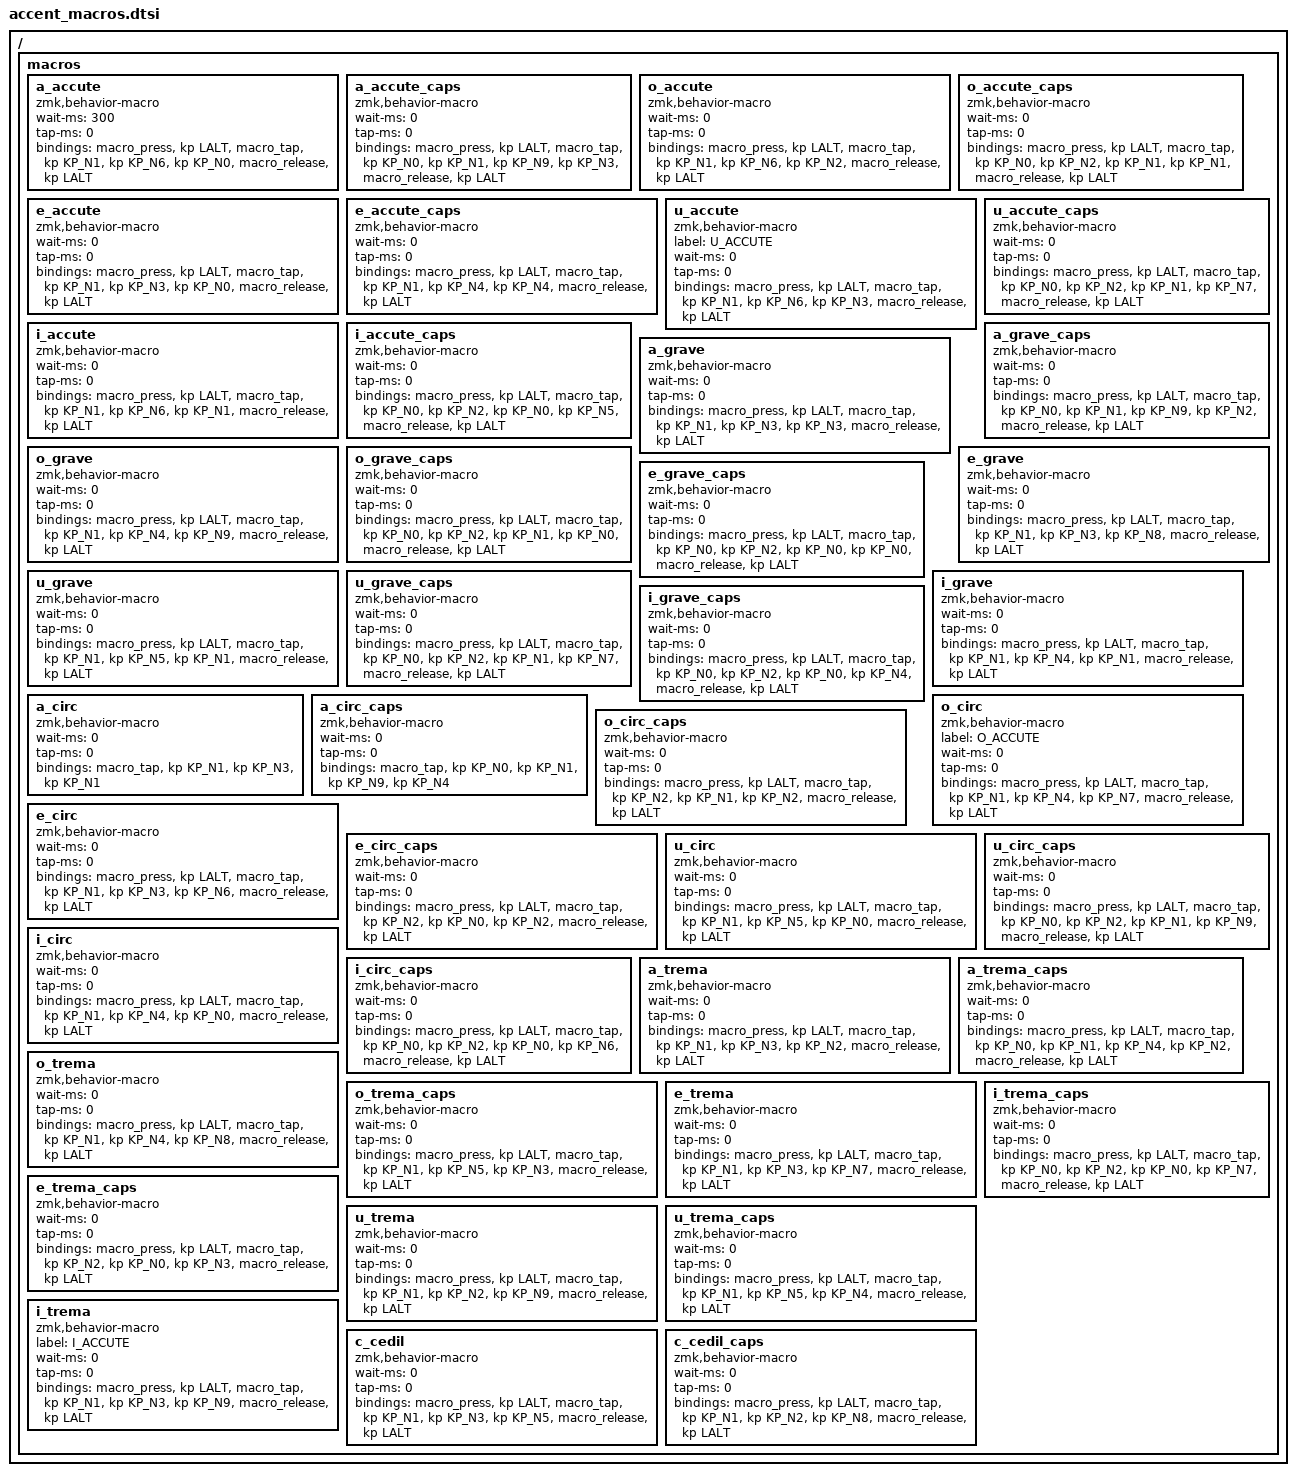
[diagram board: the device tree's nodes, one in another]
/ {
    macros {
        a_accute: a_accute {
            compatible = "zmk,behavior-macro";
            #binding-cells = <0>;
            wait-ms = <300>;
            tap-ms = <0>;
            bindings
            = <&macro_press   &kp LALT>
            , <&macro_tap     &kp KP_N1 &kp KP_N6 &kp KP_N0>
            , <&macro_release &kp LALT>;
        };

        a_accute_caps: a_accute_caps {
            compatible = "zmk,behavior-macro";
            #binding-cells = <0>;
            wait-ms = <0>;
            tap-ms = <0>;
            bindings
            = <&macro_press   &kp LALT>
            , <&macro_tap     &kp KP_N0 &kp KP_N1 &kp KP_N9 &kp KP_N3>
            , <&macro_release &kp LALT>;
        };

        o_accute: o_accute {
            compatible = "zmk,behavior-macro";
            #binding-cells = <0>;
            wait-ms = <0>;
            tap-ms = <0>;
            bindings
            = <&macro_press   &kp LALT>
            , <&macro_tap     &kp KP_N1 &kp KP_N6 &kp KP_N2>
            , <&macro_release &kp LALT>;
        };

        o_accute_caps: o_accute_caps {
            compatible = "zmk,behavior-macro";
            #binding-cells = <0>;
            wait-ms = <0>;
            tap-ms = <0>;
            bindings
            = <&macro_press   &kp LALT>
            , <&macro_tap     &kp KP_N0 &kp KP_N2 &kp KP_N1 &kp KP_N1>
            , <&macro_release &kp LALT>;
        };

        e_accute: e_accute {
            compatible = "zmk,behavior-macro";
            #binding-cells = <0>;
            wait-ms = <0>;
            tap-ms = <0>;
            bindings
            = <&macro_press   &kp LALT>
            , <&macro_tap     &kp KP_N1 &kp KP_N3 &kp KP_N0>
            , <&macro_release &kp LALT>;
        };

        e_accute_caps: e_accute_caps {
            compatible = "zmk,behavior-macro";
            #binding-cells = <0>;
            wait-ms = <0>;
            tap-ms = <0>;
            bindings
            = <&macro_press   &kp LALT>
            , <&macro_tap     &kp KP_N1 &kp KP_N4 &kp KP_N4>
            , <&macro_release &kp LALT>;
        };

        u_accute: u_accute {
            label = "U_ACCUTE";
            compatible = "zmk,behavior-macro";
            #binding-cells = <0>;
            wait-ms = <0>;
            tap-ms = <0>;
            bindings
            = <&macro_press   &kp LALT>
            , <&macro_tap     &kp KP_N1 &kp KP_N6 &kp KP_N3>
            , <&macro_release &kp LALT>;
        };

        u_accute_caps: u_accute_caps {
            compatible = "zmk,behavior-macro";
            #binding-cells = <0>;
            wait-ms = <0>;
            tap-ms = <0>;
            bindings
            = <&macro_press   &kp LALT>
            , <&macro_tap     &kp KP_N0 &kp KP_N2 &kp KP_N1 &kp KP_N7>
            , <&macro_release &kp LALT>;
        };

        i_accute: i_accute {
            compatible = "zmk,behavior-macro";
            #binding-cells = <0>;
            wait-ms = <0>;
            tap-ms = <0>;
            bindings
            = <&macro_press   &kp LALT>
            , <&macro_tap     &kp KP_N1 &kp KP_N6 &kp KP_N1>
            , <&macro_release &kp LALT>;
        };

        i_accute_caps: i_accute_caps {
            compatible = "zmk,behavior-macro";
            #binding-cells = <0>;
            wait-ms = <0>;
            tap-ms = <0>;
            bindings
            = <&macro_press   &kp LALT>
            , <&macro_tap     &kp KP_N0 &kp KP_N2 &kp KP_N0 &kp KP_N5>
            , <&macro_release &kp LALT>;
        };


        a_grave: a_grave {
            compatible = "zmk,behavior-macro";
            #binding-cells = <0>;
            wait-ms = <0>;
            tap-ms = <0>;
            bindings
            = <&macro_press   &kp LALT>
            , <&macro_tap     &kp KP_N1 &kp KP_N3 &kp KP_N3>
            , <&macro_release &kp LALT>;
        };

        a_grave_caps: a_grave_caps {
            compatible = "zmk,behavior-macro";
            #binding-cells = <0>;
            wait-ms = <0>;
            tap-ms = <0>;
            bindings
            = <&macro_press   &kp LALT>
            , <&macro_tap     &kp KP_N0 &kp KP_N1 &kp KP_N9 &kp KP_N2>
            , <&macro_release &kp LALT>;
        };

        o_grave: o_grave {
            compatible = "zmk,behavior-macro";
            #binding-cells = <0>;
            wait-ms = <0>;
            tap-ms = <0>;
            bindings
            = <&macro_press   &kp LALT>
            , <&macro_tap     &kp KP_N1 &kp KP_N4 &kp KP_N9>
            , <&macro_release &kp LALT>;
        };

        o_grave_caps: o_grave_caps {
            compatible = "zmk,behavior-macro";
            #binding-cells = <0>;
            wait-ms = <0>;
            tap-ms = <0>;
            bindings
            = <&macro_press   &kp LALT>
            , <&macro_tap     &kp KP_N0 &kp KP_N2 &kp KP_N1 &kp KP_N0>
            , <&macro_release &kp LALT>;
        };

        e_grave: e_grave {
            compatible = "zmk,behavior-macro";
            #binding-cells = <0>;
            wait-ms = <0>;
            tap-ms = <0>;
            bindings
            = <&macro_press   &kp LALT>
            , <&macro_tap     &kp KP_N1 &kp KP_N3 &kp KP_N8>
            , <&macro_release &kp LALT>;
        };

        e_grave_caps: e_grave_caps {
            compatible = "zmk,behavior-macro";
            #binding-cells = <0>;
            wait-ms = <0>;
            tap-ms = <0>;
            bindings
            = <&macro_press   &kp LALT>
            , <&macro_tap     &kp KP_N0 &kp KP_N2 &kp KP_N0 &kp KP_N0>
            , <&macro_release &kp LALT>;
        };

        u_grave: u_grave {
            compatible = "zmk,behavior-macro";
            #binding-cells = <0>;
            wait-ms = <0>;
            tap-ms = <0>;
            bindings
            = <&macro_press   &kp LALT>
            , <&macro_tap     &kp KP_N1 &kp KP_N5 &kp KP_N1>
            , <&macro_release &kp LALT>;
        };

        u_grave_caps: u_grave_caps {
            compatible = "zmk,behavior-macro";
            #binding-cells = <0>;
            wait-ms = <0>;
            tap-ms = <0>;
            bindings
            = <&macro_press   &kp LALT>
            , <&macro_tap     &kp KP_N0 &kp KP_N2 &kp KP_N1 &kp KP_N7>
            , <&macro_release &kp LALT>;
        };

        i_grave: i_grave {
            compatible = "zmk,behavior-macro";
            #binding-cells = <0>;
            wait-ms = <0>;
            tap-ms = <0>;
            bindings
            = <&macro_press   &kp LALT>
            , <&macro_tap     &kp KP_N1 &kp KP_N4 &kp KP_N1>
            , <&macro_release &kp LALT>;
        };

        i_grave_caps: i_grave_caps {
            compatible = "zmk,behavior-macro";
            #binding-cells = <0>;
            wait-ms = <0>;
            tap-ms = <0>;
            bindings
            = <&macro_press   &kp LALT>
            , <&macro_tap     &kp KP_N0 &kp KP_N2 &kp KP_N0 &kp KP_N4>
            , <&macro_release &kp LALT>;
        };


        a_circ: a_circ {
            compatible = "zmk,behavior-macro";
            #binding-cells = <0>;
            wait-ms = <0>;
            tap-ms = <0>;
            bindings = <&macro_tap &kp KP_N1 &kp KP_N3 &kp KP_N1>;
        };

        a_circ_caps: a_circ_caps {
            compatible = "zmk,behavior-macro";
            #binding-cells = <0>;
            wait-ms = <0>;
            tap-ms = <0>;
            bindings = <&macro_tap &kp KP_N0 &kp KP_N1 &kp KP_N9 &kp KP_N4>;
        };

        o_circ: o_circ {
            label = "O_ACCUTE";
            compatible = "zmk,behavior-macro";
            #binding-cells = <0>;
            wait-ms = <0>;
            tap-ms = <0>;
            bindings
            = <&macro_press   &kp LALT>
            , <&macro_tap     &kp KP_N1 &kp KP_N4 &kp KP_N7>
            , <&macro_release &kp LALT>;
        };

        o_circ_caps: o_circ_caps {
            compatible = "zmk,behavior-macro";
            #binding-cells = <0>;
            wait-ms = <0>;
            tap-ms = <0>;
            bindings
            = <&macro_press   &kp LALT>
            , <&macro_tap     &kp KP_N2 &kp KP_N1 &kp KP_N2>
            , <&macro_release &kp LALT>;
        };

        e_circ: e_circ {
            compatible = "zmk,behavior-macro";
            #binding-cells = <0>;
            wait-ms = <0>;
            tap-ms = <0>;
            bindings
            = <&macro_press   &kp LALT>
            , <&macro_tap     &kp KP_N1 &kp KP_N3 &kp KP_N6>
            , <&macro_release &kp LALT>;
        };

        e_circ_caps: e_circ_caps {
            compatible = "zmk,behavior-macro";
            #binding-cells = <0>;
            wait-ms = <0>;
            tap-ms = <0>;
            bindings
            = <&macro_press   &kp LALT>
            , <&macro_tap     &kp KP_N2 &kp KP_N0 &kp KP_N2>
            , <&macro_release &kp LALT>;
        };

        u_circ: u_circ {
            compatible = "zmk,behavior-macro";
            #binding-cells = <0>;
            wait-ms = <0>;
            tap-ms = <0>;
            bindings
            = <&macro_press   &kp LALT>
            , <&macro_tap     &kp KP_N1 &kp KP_N5 &kp KP_N0>
            , <&macro_release &kp LALT>;
        };

        u_circ_caps: u_circ_caps {
            compatible = "zmk,behavior-macro";
            #binding-cells = <0>;
            wait-ms = <0>;
            tap-ms = <0>;
            bindings
            = <&macro_press   &kp LALT>
            , <&macro_tap     &kp KP_N0 &kp KP_N2 &kp KP_N1 &kp KP_N9>
            , <&macro_release &kp LALT>;
        };

        i_circ: i_circ {
            compatible = "zmk,behavior-macro";
            #binding-cells = <0>;
            wait-ms = <0>;
            tap-ms = <0>;
            bindings
            = <&macro_press   &kp LALT>
            , <&macro_tap     &kp KP_N1 &kp KP_N4 &kp KP_N0>
            , <&macro_release &kp LALT>;
        };

        i_circ_caps: i_circ_caps {
            compatible = "zmk,behavior-macro";
            #binding-cells = <0>;
            wait-ms = <0>;
            tap-ms = <0>;
            bindings
            = <&macro_press   &kp LALT>
            , <&macro_tap     &kp KP_N0 &kp KP_N2 &kp KP_N0 &kp KP_N6>
            , <&macro_release &kp LALT>;
        };

        a_trema: a_trema {
            compatible = "zmk,behavior-macro";
            #binding-cells = <0>;
            wait-ms = <0>;
            tap-ms = <0>;
            bindings
            = <&macro_press   &kp LALT>
            , <&macro_tap     &kp KP_N1 &kp KP_N3 &kp KP_N2>
            , <&macro_release &kp LALT>;
        };

        a_trema_caps: a_trema_caps {
            compatible = "zmk,behavior-macro";
            #binding-cells = <0>;
            wait-ms = <0>;
            tap-ms = <0>;
            bindings
            = <&macro_press   &kp LALT>
            , <&macro_tap     &kp KP_N0 &kp KP_N1 &kp KP_N4 &kp KP_N2>
            , <&macro_release &kp LALT>;
        };

        o_trema: o_trema {
            compatible = "zmk,behavior-macro";
            #binding-cells = <0>;
            wait-ms = <0>;
            tap-ms = <0>;
            bindings
            = <&macro_press   &kp LALT>
            , <&macro_tap     &kp KP_N1 &kp KP_N4 &kp KP_N8>
            , <&macro_release &kp LALT>;
        };

        o_trema_caps: o_trema_caps {
            compatible = "zmk,behavior-macro";
            #binding-cells = <0>;
            wait-ms = <0>;
            tap-ms = <0>;
            bindings
            = <&macro_press   &kp LALT>
            , <&macro_tap     &kp KP_N1 &kp KP_N5 &kp KP_N3>
            , <&macro_release &kp LALT>;
        };

        e_trema: e_trema {
            compatible = "zmk,behavior-macro";
            #binding-cells = <0>;
            wait-ms = <0>;
            tap-ms = <0>;
            bindings
            = <&macro_press   &kp LALT>
            , <&macro_tap     &kp KP_N1 &kp KP_N3 &kp KP_N7>
            , <&macro_release &kp LALT>;
        };

        e_trema_caps: e_trema_caps {
            compatible = "zmk,behavior-macro";
            #binding-cells = <0>;
            wait-ms = <0>;
            tap-ms = <0>;
            bindings
            = <&macro_press   &kp LALT>
            , <&macro_tap     &kp KP_N2 &kp KP_N0 &kp KP_N3>
            , <&macro_release &kp LALT>;
        };

        u_trema: u_trema {
            compatible = "zmk,behavior-macro";
            #binding-cells = <0>;
            wait-ms = <0>;
            tap-ms = <0>;
            bindings
            = <&macro_press   &kp LALT>
            , <&macro_tap     &kp KP_N1 &kp KP_N2 &kp KP_N9>
            , <&macro_release &kp LALT>;
        };

        u_trema_caps: u_trema_caps {
            compatible = "zmk,behavior-macro";
            #binding-cells = <0>;
            wait-ms = <0>;
            tap-ms = <0>;
            bindings
            = <&macro_press   &kp LALT>
            , <&macro_tap     &kp KP_N1 &kp KP_N5 &kp KP_N4>
            , <&macro_release &kp LALT>;
        };

        i_trema: i_trema {
            label = "I_ACCUTE";
            compatible = "zmk,behavior-macro";
            #binding-cells = <0>;
            wait-ms = <0>;
            tap-ms = <0>;
            bindings
            = <&macro_press   &kp LALT>
            , <&macro_tap     &kp KP_N1 &kp KP_N3 &kp KP_N9>
            , <&macro_release &kp LALT>;
        };

        i_trema_caps: i_trema_caps {
            compatible = "zmk,behavior-macro";
            #binding-cells = <0>;
            wait-ms = <0>;
            tap-ms = <0>;
            bindings
            = <&macro_press   &kp LALT>
            , <&macro_tap     &kp KP_N0 &kp KP_N2 &kp KP_N0 &kp KP_N7>
            , <&macro_release &kp LALT>;
        };

        c_cedil: c_cedil {
            compatible = "zmk,behavior-macro";
            #binding-cells = <0>;
            wait-ms = <0>;
            tap-ms = <0>;
            bindings
            = <&macro_press   &kp LALT>
            , <&macro_tap     &kp KP_N1 &kp KP_N3 &kp KP_N5>
            , <&macro_release &kp LALT>;
        };

        c_cedil_caps: c_cedil_caps {
            compatible = "zmk,behavior-macro";
            #binding-cells = <0>;
            wait-ms = <0>;
            tap-ms = <0>;
            bindings
            = <&macro_press   &kp LALT>
            , <&macro_tap     &kp KP_N1 &kp KP_N2 &kp KP_N8>
            , <&macro_release &kp LALT>;
        };
    };
};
